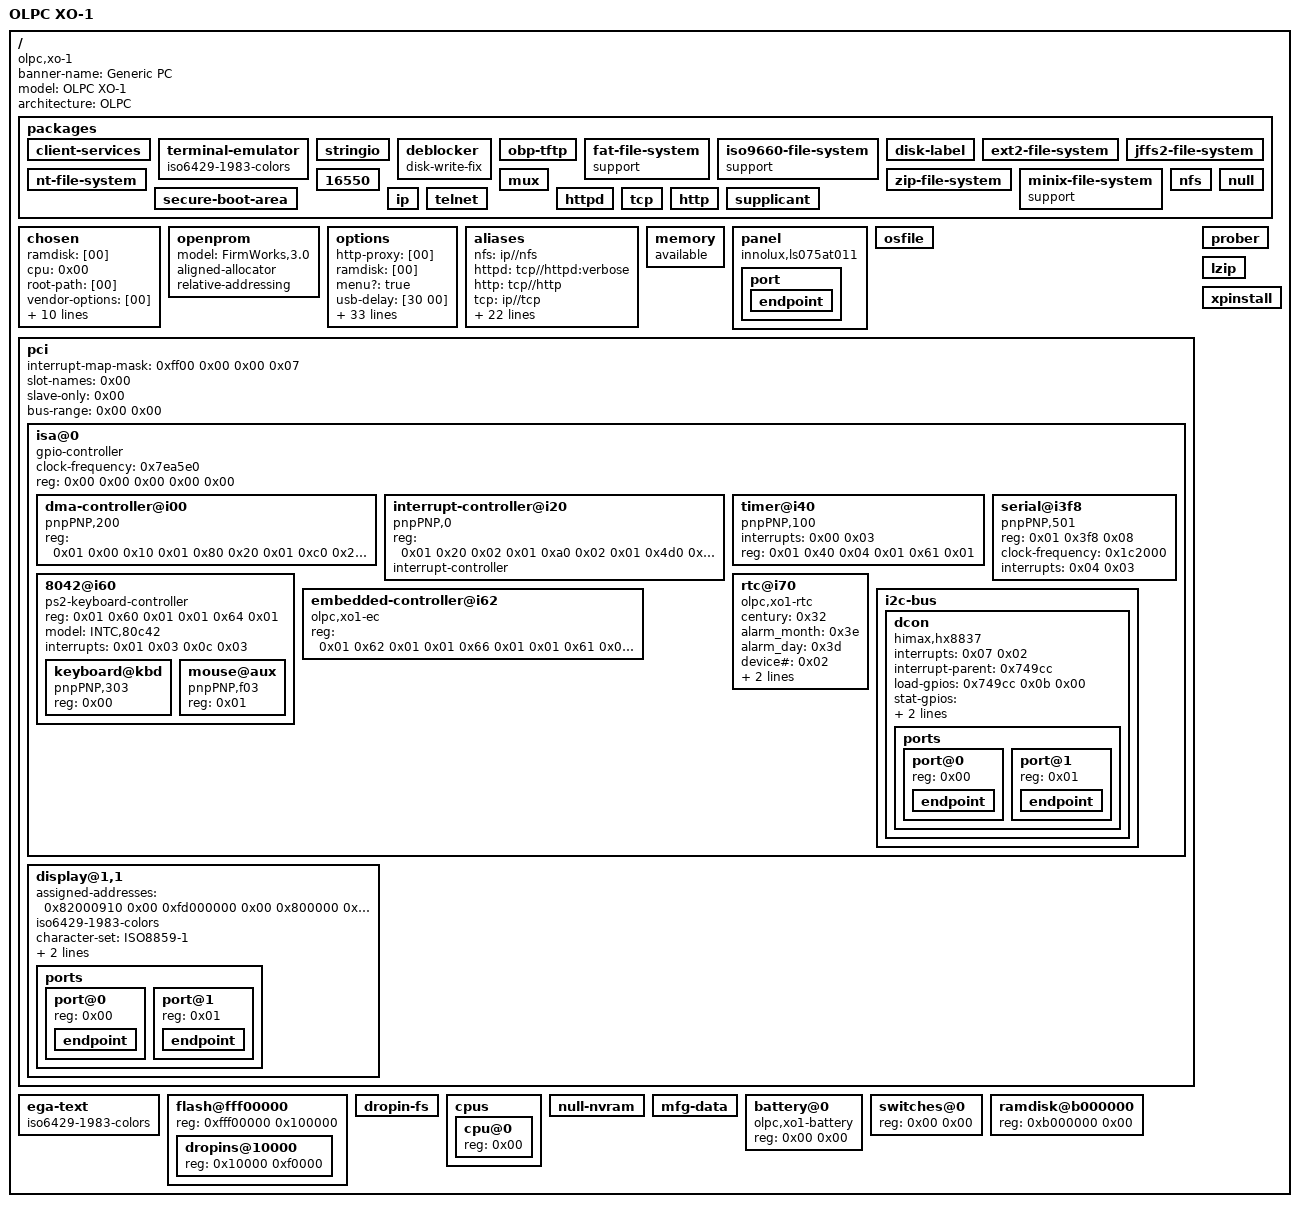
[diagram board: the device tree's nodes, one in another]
/dts-v1/;

/ {
	phandle = <0x2bb18>;
	banner-name = "Generic PC";
	compatible = "olpc,xo-1\0amd,geode-lx";
	model = "OLPC XO-1";
	architecture = "OLPC";
	#size-cells = <0x01>;
	#address-cells = <0x01>;

	packages {
		phandle = <0x2fc20>;

		client-services {
			phandle = <0x2fc54>;
		};

		terminal-emulator {
			phandle = <0x3bb0c>;
			iso6429-1983-colors;
		};

		stringio {
			phandle = <0x3e79c>;
		};

		deblocker {
			phandle = <0x3fb60>;
			disk-write-fix;
		};

		obp-tftp {
			phandle = <0x41214>;
		};

		fat-file-system {
			phandle = <0x4e9e0>;
			support;
		};

		iso9660-file-system {
			phandle = <0x53ecc>;
			support;
		};

		disk-label {
			phandle = <0x54d58>;
		};

		ext2-file-system {
			phandle = <0x5e1b8>;
		};

		jffs2-file-system {
			phandle = <0x6465c>;
		};

		nt-file-system {
			phandle = <0x67fcc>;
		};

		zip-file-system {
			phandle = <0x68110>;
		};

		minix-file-system {
			phandle = <0x694f4>;
			support;
		};

		16550 {
			phandle = <0x77298>;
		};

		mux {
			phandle = <0x7e164>;
		};

		nfs {
			phandle = <0x91498>;
		};

		null {
			phandle = <0x9709c>;
		};

		secure-boot-area {
			phandle = <0xb5a7c>;
		};

		ip {
			phandle = <0xb96fc>;
		};

		telnet {
			phandle = <0xbc370>;
		};

		httpd {
			phandle = <0xbd2d8>;
		};

		tcp {
			phandle = <0xbff08>;
		};

		http {
			phandle = <0xc5654>;
		};

		supplicant {
			phandle = <0xc6af8>;
		};
	};

	chosen {
		phandle = <0x2fcc0>;
		ramdisk = [00];
		cpu = <0x00>;
		root-path = [00];
		vendor-options = [00];
		client-name = [00];
		tftp-file = [00];
		domain-name = [00];
		bootargs = [00];
		bootpath = [00];
		nvram = <0x00>;
		mmu = <0x00>;
		memory = <0x00>;
		clock = <0x00>;
		stdout-#lines = <0x00>;
		#address-cells = <0x01>;
		#size-cells = <0x01>;
		ranges;
	};

	openprom {
		phandle = <0x2fd64>;
		model = "FirmWorks,3.0";
		aligned-allocator;
		relative-addressing;
	};

	options {
		phandle = <0x2fdf8>;
		http-proxy = [00];
		ramdisk = [00];
		menu? = "true";
		usb-delay = [30 00];
		client-symbols? = "false";
		fcode-debug? = "true";
		ip-address = "dhcp";
		ip-router = [00];
		ip-domain = [00];
		ip-netmask = "255.255.255.0";
		ip-dns-server = [00];
		local-mac-address? = "true";
		oem-logo;
		oem-logo? = "false";
		oem-banner = [00];
		oem-banner? = "false";
		output-device = "screen";
		input-device = "keyboard";
		load-base = "8388608";
		boot-command = "boot";
		auto-boot? = "true";
		watchdog-reboot? = "false";
		diag-file = [00];
		diag-device = "net";
		boot-file = [00];
		boot-device = "disk:\\boot\\olpc.fth sd:\\boot\\olpc.fth nand:\\boot\\olpc.fth /prober /usb/ethernet /usb/wlan";
		ansi-terminal? = "true";
		screen-#columns = "80";
		screen-#rows = "34";
		silent-mode? = "false";
		use-nvramrc? = "false";
		nvramrc = [00];
		security-password;
		security-#badlogins = [30 00];
		security-mode = "none";
		diag-switch? = "false";
	};

	aliases {
		phandle = <0x2fe44>;
		nfs = "ip//nfs";
		httpd = "tcp//httpd:verbose";
		http = "tcp//http";
		tcp = "ip//tcp";
		ip = "//ip";
		int-sba = "int:0//secure-boot-area//zip-file-system";
		ext-sba = "ext:0//secure-boot-area//zip-file-system";
		net = "/usb/wlan";
		u = "/usb/disk";
		usb2 = "/usb@f,5";
		usb1 = "/usb@f,4";
		screen = "/display";
		mtd = "/nandflash";
		nand = "/nandflash";
		ext = "sd";
		int = "nand";
		sd = "/sd/disk";
		n = "nand";
		d = "disk";
		mouse = "/isa/8042/mouse";
		com1 = "/isa/serial@i3f8:115200";
		keyboard = "/isa/8042/keyboard";
		rom = "/dropin-fs";
		dropins = "/dropins";
	};

	memory {
		phandle = <0x5c644>;
		available;
		device_type = "memory";
	};

	panel {
		phandle = <0x5d6c4>;
		compatible = "innolux,ls075at011\0simple-panel";

		port {
			phandle = <0x5d73c>;

			endpoint {
				phandle = <0x5d76c>;
			};
		};
	};

	osfile {
		phandle = <0x6aa20>;
	};

	pci {
		phandle = <0x6f4d0>;
		interrupt-map-mask = <0xff00 0x00 0x00 0x07>;
		#interrupt-cells = <0x01>;
		slot-names = <0x00>;
		slave-only = <0x00>;
		bus-range = <0x00 0x00>;
		#size-cells = <0x02>;
		#address-cells = <0x03>;
		device_type = "pci";

		isa@0 {
			phandle = <0x749cc>;
			#gpio-cells = <0x02>;
			gpio-controller;
			#interrupt-cells = <0x02>;
			ranges = <0x00 0x00 0x2000000 0x00 0x00 0x1000000 0x01 0x00 0x1000000 0x00 0x00 0x10000>;
			clock-frequency = <0x7ea5e0>;
			reg = <0x00 0x00 0x00 0x00 0x00>;
			#size-cells = <0x01>;
			#address-cells = <0x02>;
			device_type = "isa";

			dma-controller@i00 {
				phandle = <0x74f24>;
				reg = <0x01 0x00 0x10 0x01 0x80 0x20 0x01 0xc0 0x20 0x01 0x481 0x0f>;
				compatible = "pnpPNP,200";
				device_type = "dma-controller";
			};

			interrupt-controller@i20 {
				phandle = <0x750e4>;
				reg = <0x01 0x20 0x02 0x01 0xa0 0x02 0x01 0x4d0 0x02>;
				compatible = "pnpPNP,0";
				device_type = "interrupt-controller";
				#address-cells = <0x00>;
				#interrupt-cells = <0x02>;
				interrupt-controller;
			};

			timer@i40 {
				phandle = <0x7565c>;
				interrupts = <0x00 0x03>;
				reg = <0x01 0x40 0x04 0x01 0x61 0x01>;
				compatible = "pnpPNP,100";
				device_type = "timer";
			};

			serial@i3f8 {
				phandle = <0x78418>;
				reg = <0x01 0x3f8 0x08>;
				compatible = "pnpPNP,501";
				device_type = "serial";
				clock-frequency = <0x1c2000>;
				interrupts = <0x04 0x03>;
			};

			8042@i60 {
				phandle = <0x789ec>;
				#size-cells = <0x00>;
				#address-cells = <0x01>;
				reg = <0x01 0x60 0x01 0x01 0x64 0x01>;
				compatible = "ps2-keyboard-controller\0INTC,80c42";
				device_type = "8042";
				model = "INTC,80c42";
				interrupts = <0x01 0x03 0x0c 0x03>;

				keyboard@kbd {
					phandle = <0x797dc>;
					device_type = "keyboard";
					compatible = "pnpPNP,303";
					reg = <0x00>;
				};

				mouse@aux {
					phandle = <0x7b9f8>;
					reg = <0x01>;
					compatible = "pnpPNP,f03";
					device_type = "mouse";
				};
			};

			rtc@i70 {
				phandle = <0x7c998>;
				century = <0x32>;
				alarm_month = <0x3e>;
				alarm_day = <0x3d>;
				device# = <0x02>;
				interrupts = <0x08 0x00>;
				reg = <0x01 0x70 0x02>;
				compatible = "olpc,xo1-rtc\0pnpPNP,b00";
				device_type = "rtc";
			};

			embedded-controller@i62 {
				phandle = <0x80410>;
				reg = <0x01 0x62 0x01 0x01 0x66 0x01 0x01 0x61 0x01 0x01 0x68 0x01 0x01 0x6c 0x01 0x01 0x380 0x01>;
				compatible = "olpc,xo1-ec\0ene,kb3700\0pnpPNP,c09";
				device_type = "embedded-controller";
			};

			i2c-bus {
				phandle = <0x887a0>;
				#size-cells = <0x00>;
				#address-cells = <0x01>;

				dcon {
					phandle = <0x88c6c>;
					interrupts = <0x07 0x02>;
					interrupt-parent = <0x749cc>;
					load-gpios = <0x749cc 0x0b 0x00>;
					stat-gpios = <0x749cc 0x05 0x00 0x749cc 0x06 0x00>;
					reg = <0x0d>;
					compatible = "himax,hx8837\0olpc,xo1-dcon";

					ports {
						phandle = <0x88da4>;
						#size-cells = <0x00>;
						#address-cells = <0x01>;

						port@0 {
							phandle = <0x88e88>;
							reg = <0x00>;

							endpoint {
								phandle = <0x88ed0>;
							};
						};

						port@1 {
							phandle = <0x88f34>;
							reg = <0x01>;

							endpoint {
								phandle = <0x88f7c>;
							};
						};
					};
				};
			};
		};

		display@1,1 {
			phandle = <0x89d8c>;
			assigned-addresses = <0x82000910 0x00 0xfd000000 0x00 0x800000 0x82000914 0x00 0xfe000000 0x00 0x4000 0x82000918 0x00 0xfe004000 0x00 0x4000 0x8200091c 0x00 0xfe008000 0x00 0x4000 0x82000920 0x00 0xfe00c000 0x00 0x4000>;
			iso6429-1983-colors;
			character-set = "ISO8859-1";
			device_type = "display";
			reg = <0x900 0x00 0x00 0x00 0x100 0x2000910 0x00 0x00 0x00 0x800000 0x2000914 0x00 0x00 0x00 0x4000 0x2000918 0x00 0x00 0x00 0x4000 0x200091c 0x00 0x00 0x00 0x4000 0x2000920 0x00 0x00 0x00 0x4000>;

			ports {
				phandle = <0x8b8c0>;
				#size-cells = <0x00>;
				#address-cells = <0x01>;

				port@0 {
					phandle = <0x8b9a4>;
					reg = <0x00>;

					endpoint {
						phandle = <0x8b9ec>;
					};
				};

				port@1 {
					phandle = <0x8ba50>;
					reg = <0x01>;

					endpoint {
						phandle = <0x8ba98>;
					};
				};
			};
		};
	};

	ega-text {
		phandle = <0x73e54>;
		iso6429-1983-colors;
		device_type = "display";
	};

	flash@fff00000 {
		phandle = <0x75f20>;
		#address-cells = <0x01>;
		reg = <0xfff00000 0x100000>;

		dropins@10000 {
			phandle = <0x764c4>;
			reg = <0x10000 0xf0000>;
		};
	};

	dropin-fs {
		phandle = <0x76708>;
	};

	cpus {
		phandle = <0x7d2a8>;
		#size-cells = <0x00>;
		#address-cells = <0x01>;

		cpu@0 {
			phandle = <0x7d38c>;
			reg = <0x00>;
			device_type = "cpu";
		};
	};

	null-nvram {
		phandle = <0x7da64>;
	};

	mfg-data {
		phandle = <0x82988>;
	};

	battery@0 {
		phandle = <0x85ea8>;
		reg = <0x00 0x00>;
		compatible = "olpc,xo1-battery";
	};

	prober {
		phandle = <0x96350>;
	};

	switches@0 {
		phandle = <0xa04cc>;
		reg = <0x00 0x00>;
	};

	lzip {
		phandle = <0xa7b20>;
	};

	xpinstall {
		phandle = <0xafeb4>;
	};

	ramdisk@b000000 {
		phandle = <0xb578c>;
		reg = <0xb000000 0x00>;
	};
};
